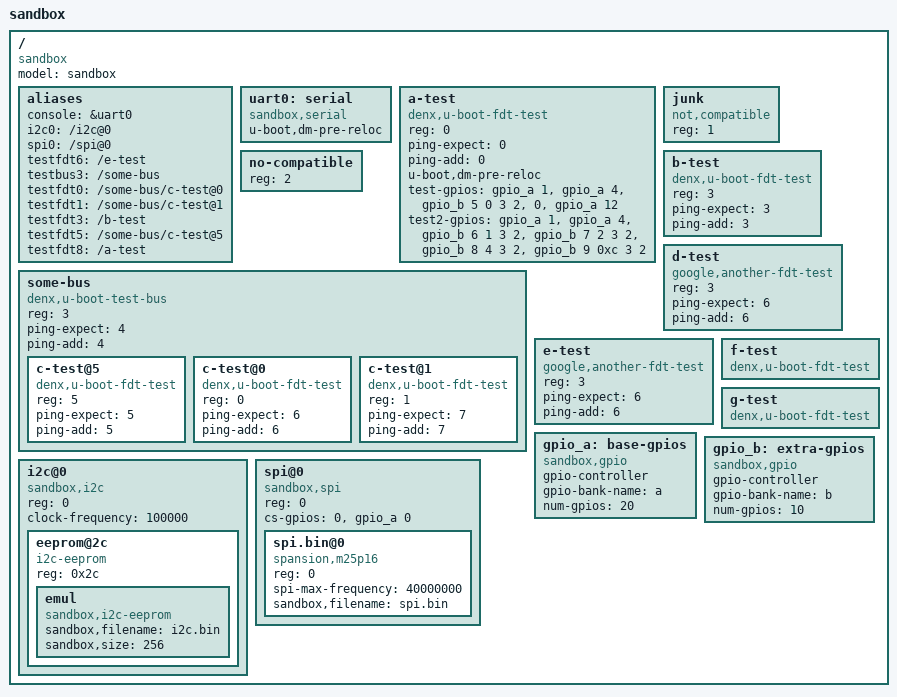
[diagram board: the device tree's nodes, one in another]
/dts-v1/;

/ {
	model = "sandbox";
	compatible = "sandbox";
	#address-cells = <1>;
	#size-cells = <0>;

	aliases {
		console = &uart0;
		i2c0 = "/i2c@0";
		spi0 = "/spi@0";
		testfdt6 = "/e-test";
		testbus3 = "/some-bus";
		testfdt0 = "/some-bus/c-test@0";
		testfdt1 = "/some-bus/c-test@1";
		testfdt3 = "/b-test";
		testfdt5 = "/some-bus/c-test@5";
		testfdt8 = "/a-test";
	};

	uart0: serial {
		compatible = "sandbox,serial";
		u-boot,dm-pre-reloc;
	};

	a-test {
		reg = <0>;
		compatible = "denx,u-boot-fdt-test";
		ping-expect = <0>;
		ping-add = <0>;
		u-boot,dm-pre-reloc;
		test-gpios = <&gpio_a 1>, <&gpio_a 4>, <&gpio_b 5 0 3 2 1>,
			<0>, <&gpio_a 12>;
		test2-gpios = <&gpio_a 1>, <&gpio_a 4>, <&gpio_b 6 1 3 2 1>,
			<&gpio_b 7 2 3 2 1>, <&gpio_b 8 4 3 2 1>,
			<&gpio_b 9 0xc 3 2 1>;
	};

	junk {
		reg = <1>;
		compatible = "not,compatible";
	};

	no-compatible {
		reg = <2>;
	};

	b-test {
		reg = <3>;
		compatible = "denx,u-boot-fdt-test";
		ping-expect = <3>;
		ping-add = <3>;
	};

	some-bus {
		#address-cells = <1>;
		#size-cells = <0>;
		compatible = "denx,u-boot-test-bus";
		reg = <3>;
		ping-expect = <4>;
		ping-add = <4>;
		c-test@5 {
			compatible = "denx,u-boot-fdt-test";
			reg = <5>;
			ping-expect = <5>;
			ping-add = <5>;
		};
		c-test@0 {
			compatible = "denx,u-boot-fdt-test";
			reg = <0>;
			ping-expect = <6>;
			ping-add = <6>;
		};
		c-test@1 {
			compatible = "denx,u-boot-fdt-test";
			reg = <1>;
			ping-expect = <7>;
			ping-add = <7>;
		};
	};

	d-test {
		reg = <3>;
		ping-expect = <6>;
		ping-add = <6>;
		compatible = "google,another-fdt-test";
	};

	e-test {
		reg = <3>;
		ping-expect = <6>;
		ping-add = <6>;
		compatible = "google,another-fdt-test";
	};

	f-test {
		compatible = "denx,u-boot-fdt-test";
	};

	g-test {
		compatible = "denx,u-boot-fdt-test";
	};

	gpio_a: base-gpios {
		compatible = "sandbox,gpio";
		gpio-controller;
		#gpio-cells = <1>;
		gpio-bank-name = "a";
		num-gpios = <20>;
	};

	gpio_b: extra-gpios {
		compatible = "sandbox,gpio";
		gpio-controller;
		#gpio-cells = <5>;
		gpio-bank-name = "b";
		num-gpios = <10>;
	};

	i2c@0 {
		#address-cells = <1>;
		#size-cells = <0>;
		reg = <0>;
		compatible = "sandbox,i2c";
		clock-frequency = <100000>;
		eeprom@2c {
			reg = <0x2c>;
			compatible = "i2c-eeprom";
			emul {
				compatible = "sandbox,i2c-eeprom";
				sandbox,filename = "i2c.bin";
				sandbox,size = <256>;
			};
		};
	};

	spi@0 {
		#address-cells = <1>;
		#size-cells = <0>;
		reg = <0>;
		compatible = "sandbox,spi";
		cs-gpios = <0>, <&gpio_a 0>;
		spi.bin@0 {
			reg = <0>;
			compatible = "spansion,m25p16", "spi-flash";
			spi-max-frequency = <40000000>;
			sandbox,filename = "spi.bin";
		};
	};

};
